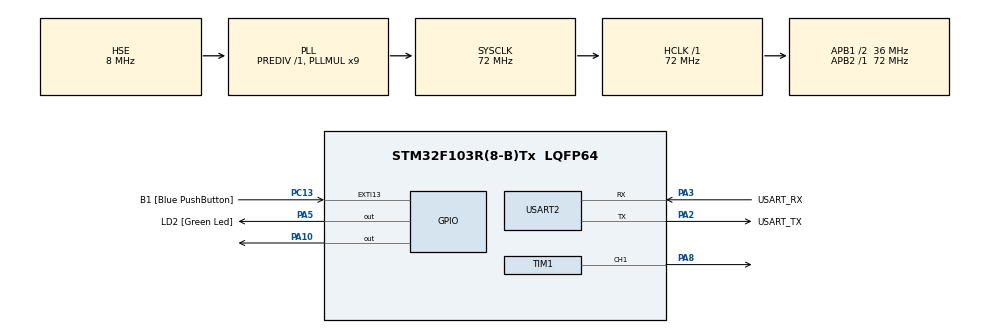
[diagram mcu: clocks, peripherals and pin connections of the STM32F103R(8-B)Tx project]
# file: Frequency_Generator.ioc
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Mcu.Family=STM32F1
Mcu.Name=STM32F103R(8-B)Tx
Mcu.Package=LQFP64
NVIC.EXTI15_10_IRQn=true\:0\:0\:false\:false\:true\:true\:true\:true
NVIC.PriorityGroup=NVIC_PRIORITYGROUP_4
PA10.GPIO_PuPd=GPIO_NOPULL
PA10.GPIO_Speed=GPIO_SPEED_FREQ_HIGH
PA10.PinState=GPIO_PIN_RESET
PA10.Signal=GPIO_Output
PA13.GPIO_Label=TMS
PA13.Mode=Serial_Wire
PA13.Signal=SYS_JTMS-SWDIO
PA14.GPIO_Label=TCK
PA14.Mode=Serial_Wire
PA14.Signal=SYS_JTCK-SWCLK
PA2.GPIO_Label=USART_TX
PA2.GPIO_Mode=GPIO_MODE_AF_PP
PA2.GPIO_PuPd=GPIO_NOPULL
PA2.GPIO_Speed=GPIO_SPEED_FREQ_LOW
PA2.Mode=Asynchronous
PA2.Signal=USART2_TX
PA3.GPIO_Label=USART_RX
PA3.GPIO_Mode=GPIO_MODE_AF_PP
PA3.GPIO_PuPd=GPIO_NOPULL
PA3.GPIO_Speed=GPIO_SPEED_FREQ_LOW
PA3.Mode=Asynchronous
PA3.Signal=USART2_RX
PA5.GPIO_Label=LD2 [Green Led]
PA5.GPIO_ModeDefaultOutputPP=GPIO_MODE_OUTPUT_PP
PA5.GPIO_PuPd=GPIO_NOPULL
PA5.GPIO_Speed=GPIO_SPEED_FREQ_LOW
PA5.Signal=GPIO_Output
PA8.GPIO_Speed=GPIO_SPEED_FREQ_HIGH
PA8.Signal=S_TIM1_CH1
PB3.GPIO_Label=SWO
PB3.Signal=SYS_JTDO-TRACESWO
PC13-TAMPER-RTC.GPIO_Label=B1 [Blue PushButton]
PC13-TAMPER-RTC.GPIO_PuPd=GPIO_NOPULL
PC13-TAMPER-RTC.Signal=GPXTI13
PC14-OSC32_IN.Mode=LSE-External-Oscillator
PC14-OSC32_IN.Signal=RCC_OSC32_IN
PC15-OSC32_OUT.Mode=LSE-External-Oscillator
PC15-OSC32_OUT.Signal=RCC_OSC32_OUT
PD0-OSC_IN.Mode=HSE-External-Oscillator
PD0-OSC_IN.Signal=RCC_OSC_IN
PD1-OSC_OUT.Mode=HSE-External-Oscillator
PD1-OSC_OUT.Signal=RCC_OSC_OUT
ProjectManager.HeapSize=0x200
ProjectManager.StackSize=0x400
ProjectManager.TargetToolchain=STM32CubeIDE
RCC.AHBFreq_Value=72000000
RCC.APB1CLKDivider=RCC_HCLK_DIV2
RCC.APB1Freq_Value=36000000
RCC.APB1TimFreq_Value=72000000
RCC.APB2Freq_Value=72000000
RCC.APB2TimFreq_Value=72000000
RCC.HCLKFreq_Value=72000000
RCC.PLLMUL=RCC_PLL_MUL9
RCC.PLLSourceVirtual=RCC_PLLSOURCE_HSE
RCC.RTCClockSelection=RCC_RTCCLKSOURCE_LSE
RCC.SYSCLKFreq_VALUE=72000000
RCC.SYSCLKSource=RCC_SYSCLKSOURCE_PLLCLK
RCC.USBFreq_Value=72000000
SH.S_TIM1_CH1.0=TIM1_CH1,PWM Generation1 CH1
TIM1.AutoReloadPreload=TIM_AUTORELOAD_PRELOAD_ENABLE
TIM1.Channel-PWM\ Generation1\ CH1=TIM_CHANNEL_1
TIM1.OCFastMode_PWM-PWM\ Generation1\ CH1=TIM_OCFAST_ENABLE
TIM1.OCMode_PWM-PWM\ Generation1\ CH1=TIM_OCMODE_PWM1
TIM1.OCPolarity_1=TIM_OCPOLARITY_LOW
TIM1.Period=2000-1
TIM1.Prescaler=72-1
TIM1.Pulse-PWM\ Generation1\ CH1=1000
USART2.VirtualMode=VM_ASYNC
VP_TIM1_VS_ClockSourceINT.Mode=Internal
board=NUCLEO-F103RB

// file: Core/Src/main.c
/* USER CODE BEGIN Header */
/**
  ******************************************************************************
  * @file           : main.c
  * @brief          : Main program body
  ******************************************************************************
  * @attention
  *
  * Copyright (c) 2024 STMicroelectronics.
  * All rights reserved.
  *
  * This software is licensed under terms that can be found in the LICENSE file
  * in the root directory of this software component.
  * If no LICENSE file comes with this software, it is provided AS-IS.
  *
  ******************************************************************************
  */
/* USER CODE END Header */
#include "main.h"

TIM_HandleTypeDef htim1;

UART_HandleTypeDef huart2;

void SystemClock_Config(void);
static void MX_GPIO_Init(void);
static void MX_USART2_UART_Init(void);
static void MX_TIM1_Init(void);

int main(void)
{

  /* MCU Configuration--------------------------------------------------------*/

  /* Reset of all peripherals, Initializes the Flash interface and the Systick. */
  HAL_Init();

  /* Configure the system clock */
  SystemClock_Config();

  /* Initialize all configured peripherals */
  MX_GPIO_Init();
  MX_USART2_UART_Init();
  MX_TIM1_Init();
  /* USER CODE BEGIN 2 */
  HAL_TIM_PWM_Start (&htim1, TIM_CHANNEL_1);
  /* USER CODE END 2 */

  /* Infinite loop */
  /* USER CODE BEGIN WHILE */
  while (1)
  {

//	  HAL_GPIO_TogglePin(GPIOA, GPIO_PIN_10);
//	  HAL_Delay(3);
    /* USER CODE END WHILE */

  }
}

void SystemClock_Config(void)
{
  RCC_OscInitTypeDef RCC_OscInitStruct = {0};
  RCC_ClkInitTypeDef RCC_ClkInitStruct = {0};

  /** Initializes the RCC Oscillators according to the specified parameters
  * in the RCC_OscInitTypeDef structure.
  */
  RCC_OscInitStruct.OscillatorType = RCC_OSCILLATORTYPE_HSE;
  RCC_OscInitStruct.HSEState = RCC_HSE_ON;
  RCC_OscInitStruct.HSEPredivValue = RCC_HSE_PREDIV_DIV1;
  RCC_OscInitStruct.HSIState = RCC_HSI_ON;
  RCC_OscInitStruct.PLL.PLLState = RCC_PLL_ON;
  RCC_OscInitStruct.PLL.PLLSource = RCC_PLLSOURCE_HSE;
  RCC_OscInitStruct.PLL.PLLMUL = RCC_PLL_MUL9;
  if (HAL_RCC_OscConfig(&RCC_OscInitStruct) != HAL_OK)
  {
    Error_Handler();
  }

  /** Initializes the CPU, AHB and APB buses clocks
  */
  RCC_ClkInitStruct.ClockType = RCC_CLOCKTYPE_HCLK|RCC_CLOCKTYPE_SYSCLK
                              |RCC_CLOCKTYPE_PCLK1|RCC_CLOCKTYPE_PCLK2;
  RCC_ClkInitStruct.SYSCLKSource = RCC_SYSCLKSOURCE_PLLCLK;
  RCC_ClkInitStruct.AHBCLKDivider = RCC_SYSCLK_DIV1;
  RCC_ClkInitStruct.APB1CLKDivider = RCC_HCLK_DIV2;
  RCC_ClkInitStruct.APB2CLKDivider = RCC_HCLK_DIV1;

  if (HAL_RCC_ClockConfig(&RCC_ClkInitStruct, FLASH_LATENCY_2) != HAL_OK)
  {
    Error_Handler();
  }
}

static void MX_TIM1_Init(void)
{

  TIM_ClockConfigTypeDef sClockSourceConfig = {0};
  TIM_MasterConfigTypeDef sMasterConfig = {0};
  TIM_OC_InitTypeDef sConfigOC = {0};
  TIM_BreakDeadTimeConfigTypeDef sBreakDeadTimeConfig = {0};

  htim1.Instance = TIM1;
  htim1.Init.Prescaler = 720-1;
  htim1.Init.CounterMode = TIM_COUNTERMODE_UP;
  htim1.Init.Period = 1200-1;
  htim1.Init.ClockDivision = TIM_CLOCKDIVISION_DIV1;
  htim1.Init.RepetitionCounter = 0;
  htim1.Init.AutoReloadPreload = TIM_AUTORELOAD_PRELOAD_ENABLE;
  if (HAL_TIM_Base_Init(&htim1) != HAL_OK)
  {
    Error_Handler();
  }
  sClockSourceConfig.ClockSource = TIM_CLOCKSOURCE_INTERNAL;
  if (HAL_TIM_ConfigClockSource(&htim1, &sClockSourceConfig) != HAL_OK)
  {
    Error_Handler();
  }
  if (HAL_TIM_PWM_Init(&htim1) != HAL_OK)
  {
    Error_Handler();
  }
  sMasterConfig.MasterOutputTrigger = TIM_TRGO_RESET;
  sMasterConfig.MasterSlaveMode = TIM_MASTERSLAVEMODE_DISABLE;
  if (HAL_TIMEx_MasterConfigSynchronization(&htim1, &sMasterConfig) != HAL_OK)
  {
    Error_Handler();
  }
  sConfigOC.OCMode = TIM_OCMODE_PWM1;
  sConfigOC.Pulse = 1000;
  sConfigOC.OCPolarity = TIM_OCPOLARITY_LOW;
  sConfigOC.OCNPolarity = TIM_OCNPOLARITY_HIGH;
  sConfigOC.OCFastMode = TIM_OCFAST_ENABLE;
  sConfigOC.OCIdleState = TIM_OCIDLESTATE_RESET;
  sConfigOC.OCNIdleState = TIM_OCNIDLESTATE_RESET;
  if (HAL_TIM_PWM_ConfigChannel(&htim1, &sConfigOC, TIM_CHANNEL_1) != HAL_OK)
  {
    Error_Handler();
  }
  sBreakDeadTimeConfig.OffStateRunMode = TIM_OSSR_DISABLE;
  sBreakDeadTimeConfig.OffStateIDLEMode = TIM_OSSI_DISABLE;
  sBreakDeadTimeConfig.LockLevel = TIM_LOCKLEVEL_OFF;
  sBreakDeadTimeConfig.DeadTime = 0;
  sBreakDeadTimeConfig.BreakState = TIM_BREAK_DISABLE;
  sBreakDeadTimeConfig.BreakPolarity = TIM_BREAKPOLARITY_HIGH;
  sBreakDeadTimeConfig.AutomaticOutput = TIM_AUTOMATICOUTPUT_DISABLE;
  if (HAL_TIMEx_ConfigBreakDeadTime(&htim1, &sBreakDeadTimeConfig) != HAL_OK)
  {
    Error_Handler();
  }
  HAL_TIM_MspPostInit(&htim1);

}

static void MX_USART2_UART_Init(void)
{

  huart2.Instance = USART2;
  huart2.Init.BaudRate = 115200;
  huart2.Init.WordLength = UART_WORDLENGTH_8B;
  huart2.Init.StopBits = UART_STOPBITS_1;
  huart2.Init.Parity = UART_PARITY_NONE;
  huart2.Init.Mode = UART_MODE_TX_RX;
  huart2.Init.HwFlowCtl = UART_HWCONTROL_NONE;
  huart2.Init.OverSampling = UART_OVERSAMPLING_16;
  if (HAL_UART_Init(&huart2) != HAL_OK)
  {
    Error_Handler();
  }

}

static void MX_GPIO_Init(void)
{
  GPIO_InitTypeDef GPIO_InitStruct = {0};

  /* GPIO Ports Clock Enable */
  __HAL_RCC_GPIOC_CLK_ENABLE();
  __HAL_RCC_GPIOD_CLK_ENABLE();
  __HAL_RCC_GPIOA_CLK_ENABLE();
  __HAL_RCC_GPIOB_CLK_ENABLE();

  /*Configure GPIO pin Output Level */
  HAL_GPIO_WritePin(GPIOA, LD2_Pin|GPIO_PIN_10, GPIO_PIN_RESET);

  /*Configure GPIO pin : B1_Pin */
  GPIO_InitStruct.Pin = B1_Pin;
  GPIO_InitStruct.Mode = GPIO_MODE_IT_RISING;
  GPIO_InitStruct.Pull = GPIO_NOPULL;
  HAL_GPIO_Init(B1_GPIO_Port, &GPIO_InitStruct);

  /*Configure GPIO pin : LD2_Pin */
  GPIO_InitStruct.Pin = LD2_Pin;
  GPIO_InitStruct.Mode = GPIO_MODE_OUTPUT_PP;
  GPIO_InitStruct.Pull = GPIO_NOPULL;
  GPIO_InitStruct.Speed = GPIO_SPEED_FREQ_LOW;
  HAL_GPIO_Init(LD2_GPIO_Port, &GPIO_InitStruct);

  /*Configure GPIO pin : PA10 */
  GPIO_InitStruct.Pin = GPIO_PIN_10;
  GPIO_InitStruct.Mode = GPIO_MODE_OUTPUT_PP;
  GPIO_InitStruct.Pull = GPIO_NOPULL;
  GPIO_InitStruct.Speed = GPIO_SPEED_FREQ_HIGH;
  HAL_GPIO_Init(GPIOA, &GPIO_InitStruct);

  /* EXTI interrupt init*/
  HAL_NVIC_SetPriority(EXTI15_10_IRQn, 0, 0);
  HAL_NVIC_EnableIRQ(EXTI15_10_IRQn);

}

void Error_Handler(void)
{
  __disable_irq();
  while (1)
  {
  }
}
